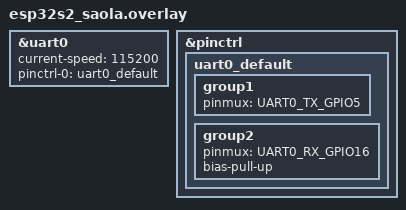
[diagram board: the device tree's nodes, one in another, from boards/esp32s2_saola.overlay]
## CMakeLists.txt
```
# SPDX-License-Identifier: Apache-2.0

cmake_minimum_required(VERSION 3.20.0)

find_package(Zephyr REQUIRED HINTS $ENV{ZEPHYR_BASE})
project(http_client0)

target_sources(app PRIVATE src/main.c)
```

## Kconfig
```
# Private config options for http-client sample app

# Copyright (c) 2020 Intel Corporation
# SPDX-License-Identifier: Apache-2.0

mainmenu "ESP32-S2 Wi-Fi options"

if WIFI_ESP32

config ESP32_WIFI_SSID
	default "MY_SSID"

config ESP32_WIFI_PASSWORD
	default "MY_PASSWORD"

endif # WIFI_ESP32

if DNS_RESOLVER

config DNS_SERVER_IP_ADDRESSES
	default y

config DNS_SERVER1
	default "1.1.1.1"

endif # DNS_RESOLVER

source "Kconfig.zephyr"
```

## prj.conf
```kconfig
# Networking config
CONFIG_NETWORKING=y
CONFIG_NET_IPV4=y
CONFIG_NET_TCP=y
#CONFIG_NET_SHELL=y

# Sockets
CONFIG_NET_SOCKETS=y
#CONFIG_NET_SOCKETS_POSIX_NAMES=y

# Network debug config
#CONFIG_LOG=y
#CONFIG_LOG_MODE_IMMEDIATE=y
#CONFIG_NET_LOG=y
#CONFIG_NET_SOCKETS_LOG_LEVEL_DBG=n

#CONFIG_MAIN_STACK_SIZE=2048
```

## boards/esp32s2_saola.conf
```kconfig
CONFIG_ESP_SPIRAM=y
CONFIG_ESP_HEAP_MIN_EXTRAM_THRESHOLD=1024

CONFIG_WIFI=y
CONFIG_WIFI_ESP32=y
CONFIG_ESP32_WIFI_NET_ALLOC_SPIRAM=y

CONFIG_NET_L2_ETHERNET=y

CONFIG_NET_DHCPV4=y

CONFIG_NET_CONFIG_LOG_LEVEL_DBG=y
CONFIG_NET_CONFIG_SETTINGS=y
CONFIG_NET_CONFIG_NEED_IPV4=y

#CONFIG_MBEDTLS_ENTROPY_ENABLED=y
#CONFIG_MBEDTLS_KEY_EXCHANGE_ECDHE_ECDSA_ENABLED=y
#CONFIG_MBEDTLS_ECP_ALL_ENABLED=y

CONFIG_ESP32_WIFI_STA_AUTO=y

CONFIG_HEAP_MEM_POOL_SIZE=29000

# when enabling NET_SHELL, the following
# helps to optimize memory footprint
CONFIG_ESP32_WIFI_STATIC_RX_BUFFER_NUM=8
CONFIG_ESP32_WIFI_DYNAMIC_RX_BUFFER_NUM=8
CONFIG_ESP32_WIFI_DYNAMIC_TX_BUFFER_NUM=8
CONFIG_ESP32_WIFI_IRAM_OPT=n
CONFIG_ESP32_WIFI_RX_IRAM_OPT=n
```

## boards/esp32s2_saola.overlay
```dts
&uart0 {
    status = "okay";
    current-speed = <115200>;
    pinctrl-0 = <&uart0_default>;
    pinctrl-names = "default";
};

&pinctrl {
    uart0_default: uart0_default {
        group1 {
            pinmux = <UART0_TX_GPIO5>;
        };
        group2 {
            pinmux = <UART0_RX_GPIO16>;
            bias-pull-up;
        };
    };
};
```

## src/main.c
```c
//#include <stdio.h>
//#include <stddef.h>
//#include <unistd.h>
//#include <sys/socket.h>
//#include <netinet/in.h>
//#include <arpa/inet.h>
//#include <string.h>

// POSIX_C_LANG_SUPPORT // strlen()
// CONFIG_NET_SOCKETS // zsock_...
// CONFIG_NET_SOCKETS_POSIX_NAMES

#include <zephyr/zephyr.h>
//#include <zephyr/kernel.h>
//#include <zephyr/logging/log.h>
//LOG_MODULE_REGISTER(net_http_client_sample, LOG_LEVEL_DBG);
#include <zephyr/net/socket.h>
#include <zephyr/net/net_ip.h>

int main() {
    int sock_fd = zsock_socket(AF_INET, SOCK_STREAM, 0);

    struct sockaddr_in sv_addr_in;
    sv_addr_in.sin_family = AF_INET;
    sv_addr_in.sin_port = htons(80);
    zsock_inet_pton(AF_INET, "52.218.49.114", &(sv_addr_in.sin_addr));

    zsock_connect(sock_fd, (struct sockaddr *) &sv_addr_in, sizeof(struct sockaddr_in));

    printk("client: writing request...\n");
    char *http_req = "GET /hello.html HTTP/1.1\r\nHost: tmb.gr\r\n\r\n";
    zsock_send(sock_fd, http_req, strlen(http_req), 0);

    printk("client: reading response...\n");
    int n = 1024;
    char buf[n];
    int r = zsock_recv(sock_fd, buf, n, 0);
    buf[r] = '\0';
    printk("%s", buf);

    zsock_close(sock_fd);
    k_sleep(K_FOREVER);
    return 0;
}
```
